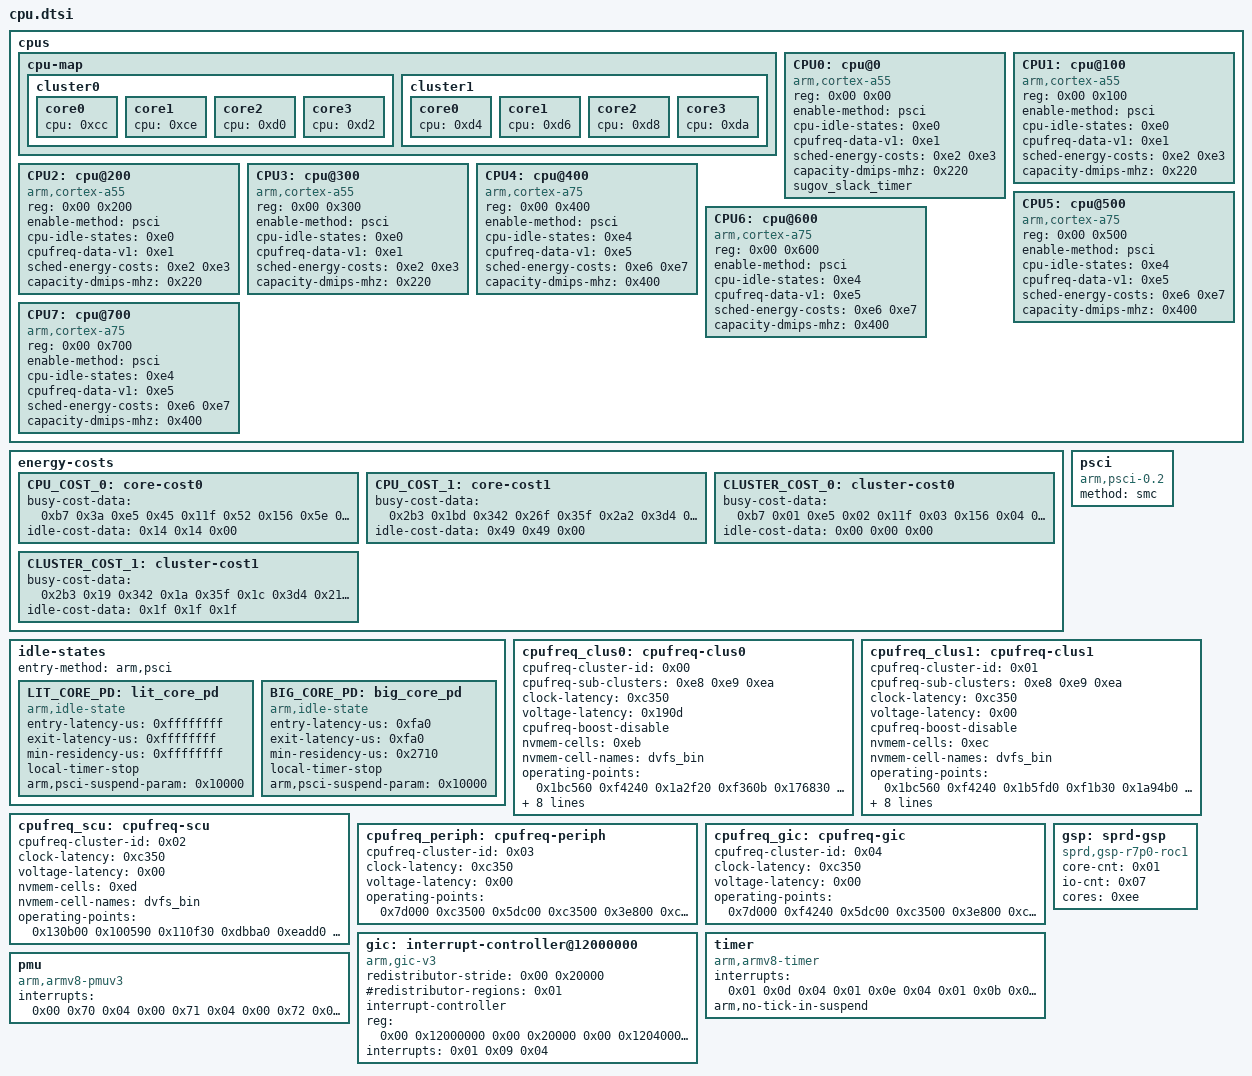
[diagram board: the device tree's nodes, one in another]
/*
 * iclass-c8pro hardware description; included in place from the board DTS.
 * Copyright (C) 2026 Evarentha - Linux 5.15 board port changes.
 */

	cpus {
		#address-cells = <0x02>;
		#size-cells = <0x00>;

		cpu-map {

			cluster0 {

				core0 {
					cpu = <0xcc>;
				};

				core1 {
					cpu = <0xce>;
				};

				core2 {
					cpu = <0xd0>;
				};

				core3 {
					cpu = <0xd2>;
				};
			};

			cluster1 {

				core0 {
					cpu = <0xd4>;
				};

				core1 {
					cpu = <0xd6>;
				};

				core2 {
					cpu = <0xd8>;
				};

				core3 {
					cpu = <0xda>;
				};
			};
		};

		CPU0: cpu@0 {
			device_type = "cpu";
			compatible = "arm,cortex-a55", "arm,armv8";
			reg = <0x00 0x00>;
			enable-method = "psci";
			cpu-idle-states = <0xe0>;
			cpufreq-data-v1 = <0xe1>;
			sched-energy-costs = <0xe2 0xe3>;
			capacity-dmips-mhz = <0x220>;
			sugov_slack_timer;
			phandle = <0xcc>;
		};

		CPU1: cpu@100 {
			device_type = "cpu";
			compatible = "arm,cortex-a55", "arm,armv8";
			reg = <0x00 0x100>;
			enable-method = "psci";
			cpu-idle-states = <0xe0>;
			cpufreq-data-v1 = <0xe1>;
			sched-energy-costs = <0xe2 0xe3>;
			capacity-dmips-mhz = <0x220>;
			phandle = <0xce>;
		};

		CPU2: cpu@200 {
			device_type = "cpu";
			compatible = "arm,cortex-a55", "arm,armv8";
			reg = <0x00 0x200>;
			enable-method = "psci";
			cpu-idle-states = <0xe0>;
			cpufreq-data-v1 = <0xe1>;
			sched-energy-costs = <0xe2 0xe3>;
			capacity-dmips-mhz = <0x220>;
			phandle = <0xd0>;
		};

		CPU3: cpu@300 {
			device_type = "cpu";
			compatible = "arm,cortex-a55", "arm,armv8";
			reg = <0x00 0x300>;
			enable-method = "psci";
			cpu-idle-states = <0xe0>;
			cpufreq-data-v1 = <0xe1>;
			sched-energy-costs = <0xe2 0xe3>;
			capacity-dmips-mhz = <0x220>;
			phandle = <0xd2>;
		};

		CPU4: cpu@400 {
			device_type = "cpu";
			compatible = "arm,cortex-a75", "arm,armv8";
			reg = <0x00 0x400>;
			enable-method = "psci";
			cpu-idle-states = <0xe4>;
			cpufreq-data-v1 = <0xe5>;
			sched-energy-costs = <0xe6 0xe7>;
			capacity-dmips-mhz = <0x400>;
			phandle = <0xd4>;
		};

		CPU5: cpu@500 {
			device_type = "cpu";
			compatible = "arm,cortex-a75", "arm,armv8";
			reg = <0x00 0x500>;
			enable-method = "psci";
			cpu-idle-states = <0xe4>;
			cpufreq-data-v1 = <0xe5>;
			sched-energy-costs = <0xe6 0xe7>;
			capacity-dmips-mhz = <0x400>;
			phandle = <0xd6>;
		};

		CPU6: cpu@600 {
			device_type = "cpu";
			compatible = "arm,cortex-a75", "arm,armv8";
			reg = <0x00 0x600>;
			enable-method = "psci";
			cpu-idle-states = <0xe4>;
			cpufreq-data-v1 = <0xe5>;
			sched-energy-costs = <0xe6 0xe7>;
			capacity-dmips-mhz = <0x400>;
			phandle = <0xd8>;
		};

		CPU7: cpu@700 {
			device_type = "cpu";
			compatible = "arm,cortex-a75", "arm,armv8";
			reg = <0x00 0x700>;
			enable-method = "psci";
			cpu-idle-states = <0xe4>;
			cpufreq-data-v1 = <0xe5>;
			sched-energy-costs = <0xe6 0xe7>;
			capacity-dmips-mhz = <0x400>;
			phandle = <0xda>;
		};
	};

	energy-costs {

		CPU_COST_0: core-cost0 {
			busy-cost-data = <0xb7 0x3a 0xe5 0x45 0x11f 0x52 0x156 0x5e 0x16f 0x6a 0x1bb 0x95 0x1cb 0x9f 0x201 0xc6 0x220 0xdf>;
			idle-cost-data = <0x14 0x14 0x00>;
			phandle = <0xe2>;
		};

		CPU_COST_1: core-cost1 {
			busy-cost-data = <0x2b3 0x1bd 0x342 0x26f 0x35f 0x2a2 0x3d4 0x373 0x3f1 0x39e 0x400 0x3bf>;
			idle-cost-data = <0x49 0x49 0x00>;
			phandle = <0xe6>;
		};

		CLUSTER_COST_0: cluster-cost0 {
			busy-cost-data = <0xb7 0x01 0xe5 0x02 0x11f 0x03 0x156 0x04 0x16f 0x05 0x1bb 0x07 0x1cb 0x08 0x201 0x09 0x220 0x0a>;
			idle-cost-data = <0x00 0x00 0x00>;
			phandle = <0xe3>;
		};

		CLUSTER_COST_1: cluster-cost1 {
			busy-cost-data = <0x2b3 0x19 0x342 0x1a 0x35f 0x1c 0x3d4 0x21 0x3f1 0x22 0x400 0x2e>;
			idle-cost-data = <0x1f 0x1f 0x1f>;
			phandle = <0xe7>;
		};
	};

	idle-states {
		entry-method = "arm,psci";

		LIT_CORE_PD: lit_core_pd {
			compatible = "arm,idle-state";
			entry-latency-us = <0xffffffff>;
			exit-latency-us = <0xffffffff>;
			min-residency-us = <0xffffffff>;
			local-timer-stop;
			arm,psci-suspend-param = <0x10000>;
			phandle = <0xe0>;
		};

		BIG_CORE_PD: big_core_pd {
			compatible = "arm,idle-state";
			entry-latency-us = <0xfa0>;
			exit-latency-us = <0xfa0>;
			min-residency-us = <0x2710>;
			local-timer-stop;
			arm,psci-suspend-param = <0x10000>;
			phandle = <0xe4>;
		};
	};

	psci {
		compatible = "arm,psci-0.2";
		method = "smc";
	};

	cpufreq_clus0: cpufreq-clus0 {
		cpufreq-cluster-id = <0x00>;
		cpufreq-sub-clusters = <0xe8 0xe9 0xea>;
		clock-latency = <0xc350>;
		voltage-latency = <0x190d>;
		cpufreq-boost-disable;
		nvmem-cells = <0xeb>;
		nvmem-cell-names = "dvfs_bin";
		operating-points = <0x1bc560 0xf4240 0x1a2f20 0xf360b 0x176830 0xe4e1c 0x169d10 0xe1113 0x12c000 0xcdfe6 0x1174c0 0xc7209 0xeadd0 0xb964f 0xbb800 0xb71b0 0x96000 0xb71b0>;
		operating-points-1 = <0x1bc560 0xe297d 0x1a2f20 0xdaf6b 0x176830 0xcdfe6 0x169d10 0xca2dd 0x12c000 0xb7de5 0x1174c0 0xb71b0 0xeadd0 0xb71b0 0xbb800 0xb71b0 0x96000 0xb71b0>;
		operating-points-2 = <0x1bc560 0xea38f 0x1a2f20 0xe297d 0x176830 0xd4dc3 0x169d10 0xd10ba 0x12c000 0xbdf8d 0x1174c0 0xb7de5 0xeadd0 0xb71b0 0xbb800 0xb71b0 0x96000 0xb71b0>;
		operating-points-3 = <0x1bc560 0xef902 0x1a2f20 0xe7ef0 0x176830 0xda336 0x169d10 0xd662d 0x12c000 0xc3500 0x1174c0 0xbd358 0xeadd0 0xb71b0 0xbb800 0xb71b0 0x96000 0xb71b0>;
		operating-points-4 = <0x1bc560 0xf4240 0x1a2f20 0xf360b 0x176830 0xe4e1c 0x169d10 0xe1113 0x12c000 0xcdfe6 0x1174c0 0xc7209 0xeadd0 0xb964f 0xbb800 0xb71b0 0x96000 0xb71b0>;
		phandle = <0xe1>;
	};

	cpufreq_clus1: cpufreq-clus1 {
		cpufreq-cluster-id = <0x01>;
		cpufreq-sub-clusters = <0xe8 0xe9 0xea>;
		clock-latency = <0xc350>;
		voltage-latency = <0x00>;
		cpufreq-boost-disable;
		nvmem-cells = <0xec>;
		nvmem-cell-names = "dvfs_bin";
		operating-points = <0x1bc560 0xf4240 0x1b5fd0 0xf1b30 0x1a94b0 0xef420 0x176830 0xe09c0 0x169d10 0xdbba0 0x12c000 0xcaa30>;
		operating-points-1 = <0x1bc560 0xdbba0 0x1b5fd0 0xd9490 0x1a94b0 0xd4670 0x176830 0xc3500 0x169d10 0xbe6e0 0x12c000 0xb71b0>;
		operating-points-2 = <0x1bc560 0xe30d0 0x1b5fd0 0xe09c0 0x1a94b0 0xde2b0 0x176830 0xcd140 0x169d10 0xc8320 0x12c000 0xb71b0>;
		operating-points-3 = <0x1bc560 0xe7ef0 0x1b5fd0 0xe57e0 0x1a94b0 0xe30d0 0x176830 0xd1f60 0x169d10 0xcd140 0x12c000 0xb98c0>;
		operating-points-4 = <0x1bc560 0xf4240 0x1b5fd0 0xf1b30 0x1a94b0 0xef420 0x176830 0xe09c0 0x169d10 0xdbba0 0x12c000 0xcaa30>;
		phandle = <0xe5>;
	};

	cpufreq_scu: cpufreq-scu {
		cpufreq-cluster-id = <0x02>;
		clock-latency = <0xc350>;
		voltage-latency = <0x00>;
		nvmem-cells = <0xed>;
		nvmem-cell-names = "dvfs_bin";
		operating-points = <0x130b00 0x100590 0x110f30 0xdbba0 0xeadd0 0xdbba0 0xd1790 0xc3500 0xbb800 0xc3500 0x9eb10 0xb71b0 0x7ef40 0xb71b0>;
		phandle = <0xe8>;
	};

	cpufreq_periph: cpufreq-periph {
		cpufreq-cluster-id = <0x03>;
		clock-latency = <0xc350>;
		voltage-latency = <0x00>;
		operating-points = <0x7d000 0xc3500 0x5dc00 0xc3500 0x3e800 0xc3500 0x25800 0xb71b0>;
		phandle = <0xe9>;
	};

	cpufreq_gic: cpufreq-gic {
		cpufreq-cluster-id = <0x04>;
		clock-latency = <0xc350>;
		voltage-latency = <0x00>;
		operating-points = <0x7d000 0xf4240 0x5dc00 0xc3500 0x3e800 0xc3500 0x2ee00 0xc3500 0x25800 0xb71b0>;
		phandle = <0xea>;
	};

	gic: interrupt-controller@12000000 {
		compatible = "arm,gic-v3";
		#interrupt-cells = <0x03>;
		#address-cells = <0x02>;
		#size-cells = <0x02>;
		ranges;
		redistributor-stride = <0x00 0x20000>;
		#redistributor-regions = <0x01>;
		interrupt-controller;
		reg = <0x00 0x12000000 0x00 0x20000 0x00 0x12040000 0x00 0x100000>;
		interrupts = <0x01 0x09 0x04>;
		phandle = <0x01>;
	};

	timer {
		compatible = "arm,armv8-timer";
		interrupts = <0x01 0x0d 0x04 0x01 0x0e 0x04 0x01 0x0b 0x04 0x01 0x0a 0x04>;
		arm,no-tick-in-suspend;
	};

	pmu {
		compatible = "arm,armv8-pmuv3";
		interrupts = <0x00 0x70 0x04 0x00 0x71 0x04 0x00 0x72 0x04 0x00 0x73 0x04 0x00 0x74 0x04 0x00 0x75 0x04 0x00 0x76 0x04 0x00 0x77 0x04>;
	};

	gsp: sprd-gsp {
		compatible = "sprd,gsp-r7p0-roc1";
		core-cnt = <0x01>;
		io-cnt = <0x07>;
		cores = <0xee>;
		phandle = <0x107>;
	};

